VERSION ""

NS_ :

BS_:

BU_: BMS Host

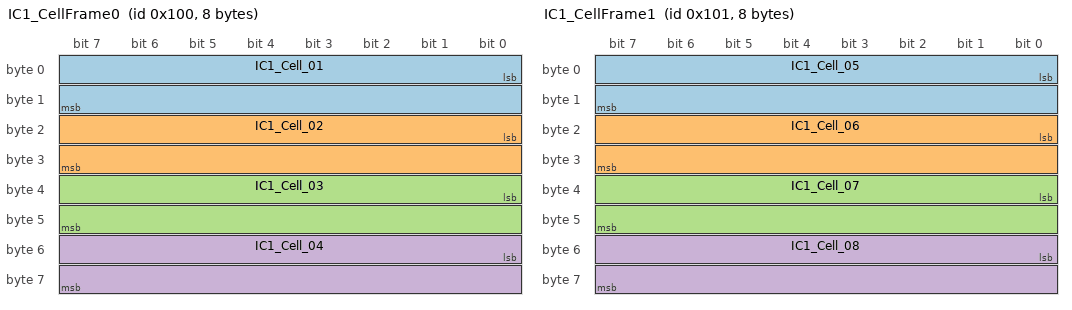
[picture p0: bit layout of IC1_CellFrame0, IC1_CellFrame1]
BO_ 256 IC1_CellFrame0: 8 BMS
 SG_ IC1_Cell_01 : 0|16@1+ (0.0001,0) [0|6.5535] "V" Host
 SG_ IC1_Cell_02 : 16|16@1+ (0.0001,0) [0|6.5535] "V" Host
 SG_ IC1_Cell_03 : 32|16@1+ (0.0001,0) [0|6.5535] "V" Host
 SG_ IC1_Cell_04 : 48|16@1+ (0.0001,0) [0|6.5535] "V" Host

BO_ 257 IC1_CellFrame1: 8 BMS
 SG_ IC1_Cell_05 : 0|16@1+ (0.0001,0) [0|6.5535] "V" Host
 SG_ IC1_Cell_06 : 16|16@1+ (0.0001,0) [0|6.5535] "V" Host
 SG_ IC1_Cell_07 : 32|16@1+ (0.0001,0) [0|6.5535] "V" Host
 SG_ IC1_Cell_08 : 48|16@1+ (0.0001,0) [0|6.5535] "V" Host

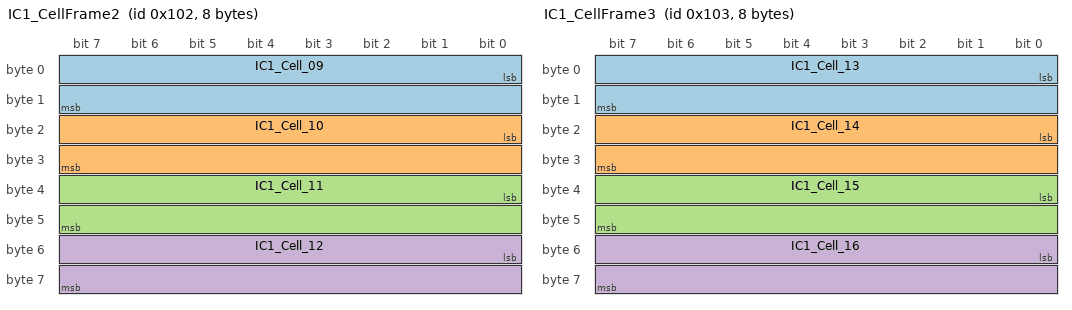
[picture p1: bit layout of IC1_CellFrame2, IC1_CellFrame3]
BO_ 258 IC1_CellFrame2: 8 BMS
 SG_ IC1_Cell_09 : 0|16@1+ (0.0001,0) [0|6.5535] "V" Host
 SG_ IC1_Cell_10 : 16|16@1+ (0.0001,0) [0|6.5535] "V" Host
 SG_ IC1_Cell_11 : 32|16@1+ (0.0001,0) [0|6.5535] "V" Host
 SG_ IC1_Cell_12 : 48|16@1+ (0.0001,0) [0|6.5535] "V" Host

BO_ 259 IC1_CellFrame3: 8 BMS
 SG_ IC1_Cell_13 : 0|16@1+ (0.0001,0) [0|6.5535] "V" Host
 SG_ IC1_Cell_14 : 16|16@1+ (0.0001,0) [0|6.5535] "V" Host
 SG_ IC1_Cell_15 : 32|16@1+ (0.0001,0) [0|6.5535] "V" Host
 SG_ IC1_Cell_16 : 48|16@1+ (0.0001,0) [0|6.5535] "V" Host

BO_ 260 IC1_CellFrame4: 8 BMS
 SG_ IC1_Cell_17 : 0|16@1+ (0.0001,0) [0|6.5535] "V" Host

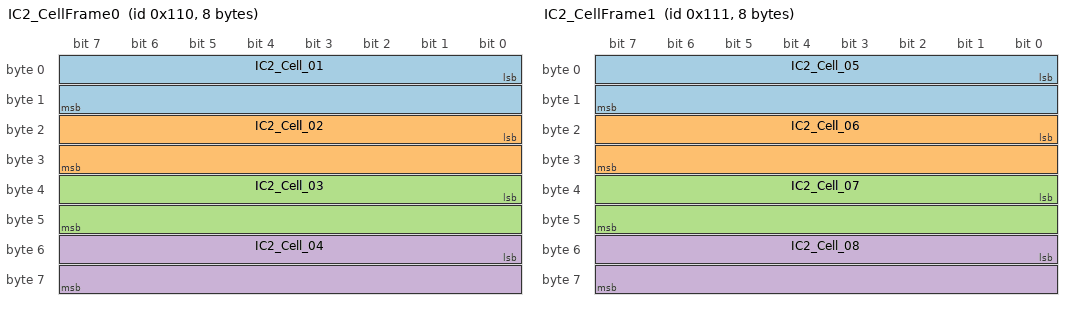
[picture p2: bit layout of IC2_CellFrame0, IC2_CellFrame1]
BO_ 272 IC2_CellFrame0: 8 BMS
 SG_ IC2_Cell_01 : 0|16@1+ (0.0001,0) [0|6.5535] "V" Host
 SG_ IC2_Cell_02 : 16|16@1+ (0.0001,0) [0|6.5535] "V" Host
 SG_ IC2_Cell_03 : 32|16@1+ (0.0001,0) [0|6.5535] "V" Host
 SG_ IC2_Cell_04 : 48|16@1+ (0.0001,0) [0|6.5535] "V" Host

BO_ 273 IC2_CellFrame1: 8 BMS
 SG_ IC2_Cell_05 : 0|16@1+ (0.0001,0) [0|6.5535] "V" Host
 SG_ IC2_Cell_06 : 16|16@1+ (0.0001,0) [0|6.5535] "V" Host
 SG_ IC2_Cell_07 : 32|16@1+ (0.0001,0) [0|6.5535] "V" Host
 SG_ IC2_Cell_08 : 48|16@1+ (0.0001,0) [0|6.5535] "V" Host

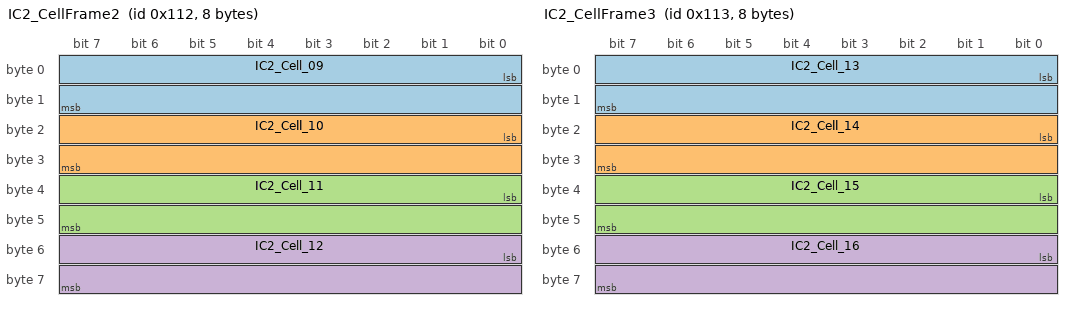
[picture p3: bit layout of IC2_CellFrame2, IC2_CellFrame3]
BO_ 274 IC2_CellFrame2: 8 BMS
 SG_ IC2_Cell_09 : 0|16@1+ (0.0001,0) [0|6.5535] "V" Host
 SG_ IC2_Cell_10 : 16|16@1+ (0.0001,0) [0|6.5535] "V" Host
 SG_ IC2_Cell_11 : 32|16@1+ (0.0001,0) [0|6.5535] "V" Host
 SG_ IC2_Cell_12 : 48|16@1+ (0.0001,0) [0|6.5535] "V" Host

BO_ 275 IC2_CellFrame3: 8 BMS
 SG_ IC2_Cell_13 : 0|16@1+ (0.0001,0) [0|6.5535] "V" Host
 SG_ IC2_Cell_14 : 16|16@1+ (0.0001,0) [0|6.5535] "V" Host
 SG_ IC2_Cell_15 : 32|16@1+ (0.0001,0) [0|6.5535] "V" Host
 SG_ IC2_Cell_16 : 48|16@1+ (0.0001,0) [0|6.5535] "V" Host

BO_ 276 IC2_CellFrame4: 8 BMS
 SG_ IC2_Cell_17 : 0|16@1+ (0.0001,0) [0|6.5535] "V" Host

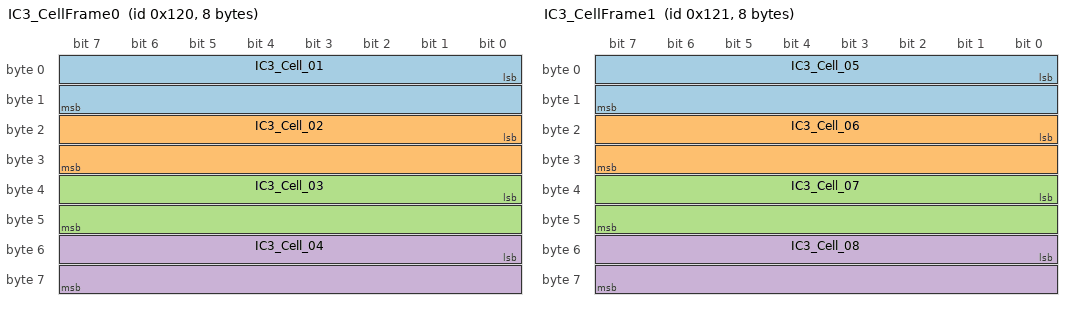
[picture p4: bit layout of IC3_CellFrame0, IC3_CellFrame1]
BO_ 288 IC3_CellFrame0: 8 BMS
 SG_ IC3_Cell_01 : 0|16@1+ (0.0001,0) [0|6.5535] "V" Host
 SG_ IC3_Cell_02 : 16|16@1+ (0.0001,0) [0|6.5535] "V" Host
 SG_ IC3_Cell_03 : 32|16@1+ (0.0001,0) [0|6.5535] "V" Host
 SG_ IC3_Cell_04 : 48|16@1+ (0.0001,0) [0|6.5535] "V" Host

BO_ 289 IC3_CellFrame1: 8 BMS
 SG_ IC3_Cell_05 : 0|16@1+ (0.0001,0) [0|6.5535] "V" Host
 SG_ IC3_Cell_06 : 16|16@1+ (0.0001,0) [0|6.5535] "V" Host
 SG_ IC3_Cell_07 : 32|16@1+ (0.0001,0) [0|6.5535] "V" Host
 SG_ IC3_Cell_08 : 48|16@1+ (0.0001,0) [0|6.5535] "V" Host

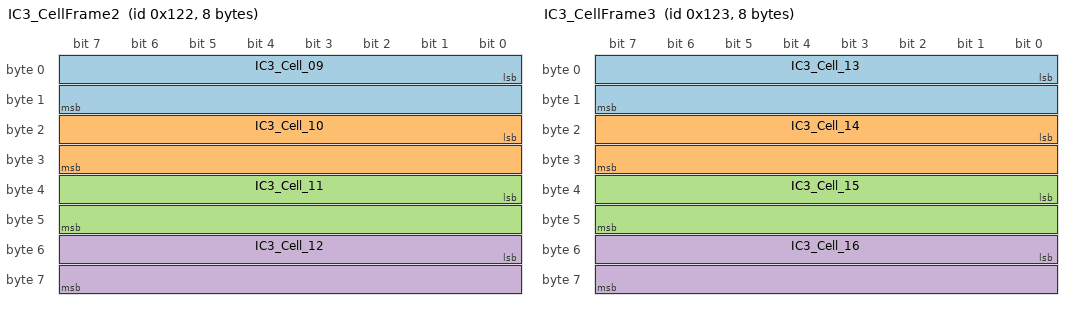
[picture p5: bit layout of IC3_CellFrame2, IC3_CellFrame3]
BO_ 290 IC3_CellFrame2: 8 BMS
 SG_ IC3_Cell_09 : 0|16@1+ (0.0001,0) [0|6.5535] "V" Host
 SG_ IC3_Cell_10 : 16|16@1+ (0.0001,0) [0|6.5535] "V" Host
 SG_ IC3_Cell_11 : 32|16@1+ (0.0001,0) [0|6.5535] "V" Host
 SG_ IC3_Cell_12 : 48|16@1+ (0.0001,0) [0|6.5535] "V" Host

BO_ 291 IC3_CellFrame3: 8 BMS
 SG_ IC3_Cell_13 : 0|16@1+ (0.0001,0) [0|6.5535] "V" Host
 SG_ IC3_Cell_14 : 16|16@1+ (0.0001,0) [0|6.5535] "V" Host
 SG_ IC3_Cell_15 : 32|16@1+ (0.0001,0) [0|6.5535] "V" Host
 SG_ IC3_Cell_16 : 48|16@1+ (0.0001,0) [0|6.5535] "V" Host

BO_ 292 IC3_CellFrame4: 8 BMS
 SG_ IC3_Cell_17 : 0|16@1+ (0.0001,0) [0|6.5535] "V" Host

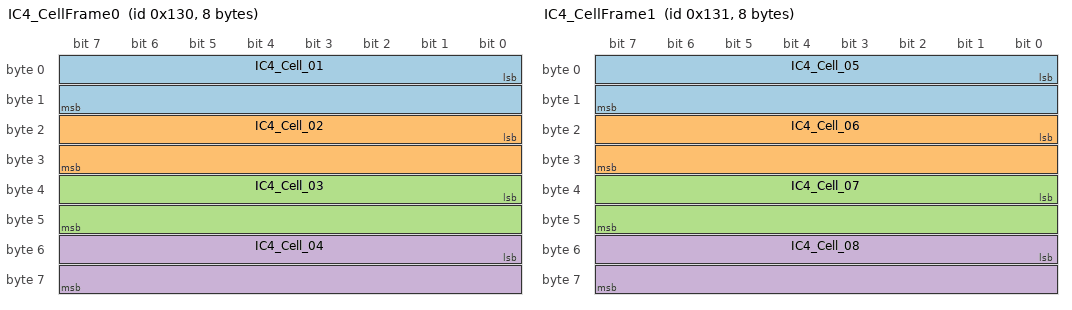
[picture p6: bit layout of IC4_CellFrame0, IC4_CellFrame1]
BO_ 304 IC4_CellFrame0: 8 BMS
 SG_ IC4_Cell_01 : 0|16@1+ (0.0001,0) [0|6.5535] "V" Host
 SG_ IC4_Cell_02 : 16|16@1+ (0.0001,0) [0|6.5535] "V" Host
 SG_ IC4_Cell_03 : 32|16@1+ (0.0001,0) [0|6.5535] "V" Host
 SG_ IC4_Cell_04 : 48|16@1+ (0.0001,0) [0|6.5535] "V" Host

BO_ 305 IC4_CellFrame1: 8 BMS
 SG_ IC4_Cell_05 : 0|16@1+ (0.0001,0) [0|6.5535] "V" Host
 SG_ IC4_Cell_06 : 16|16@1+ (0.0001,0) [0|6.5535] "V" Host
 SG_ IC4_Cell_07 : 32|16@1+ (0.0001,0) [0|6.5535] "V" Host
 SG_ IC4_Cell_08 : 48|16@1+ (0.0001,0) [0|6.5535] "V" Host

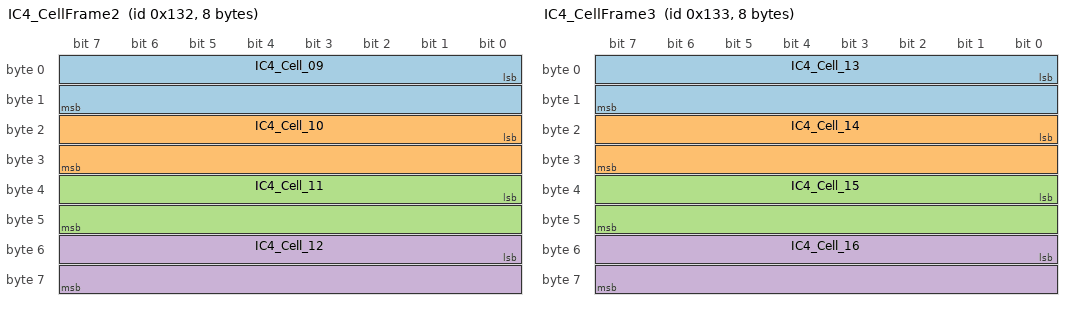
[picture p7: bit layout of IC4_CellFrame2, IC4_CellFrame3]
BO_ 306 IC4_CellFrame2: 8 BMS
 SG_ IC4_Cell_09 : 0|16@1+ (0.0001,0) [0|6.5535] "V" Host
 SG_ IC4_Cell_10 : 16|16@1+ (0.0001,0) [0|6.5535] "V" Host
 SG_ IC4_Cell_11 : 32|16@1+ (0.0001,0) [0|6.5535] "V" Host
 SG_ IC4_Cell_12 : 48|16@1+ (0.0001,0) [0|6.5535] "V" Host

BO_ 307 IC4_CellFrame3: 8 BMS
 SG_ IC4_Cell_13 : 0|16@1+ (0.0001,0) [0|6.5535] "V" Host
 SG_ IC4_Cell_14 : 16|16@1+ (0.0001,0) [0|6.5535] "V" Host
 SG_ IC4_Cell_15 : 32|16@1+ (0.0001,0) [0|6.5535] "V" Host
 SG_ IC4_Cell_16 : 48|16@1+ (0.0001,0) [0|6.5535] "V" Host

BO_ 308 IC4_CellFrame4: 8 BMS
 SG_ IC4_Cell_17 : 0|16@1+ (0.0001,0) [0|6.5535] "V" Host

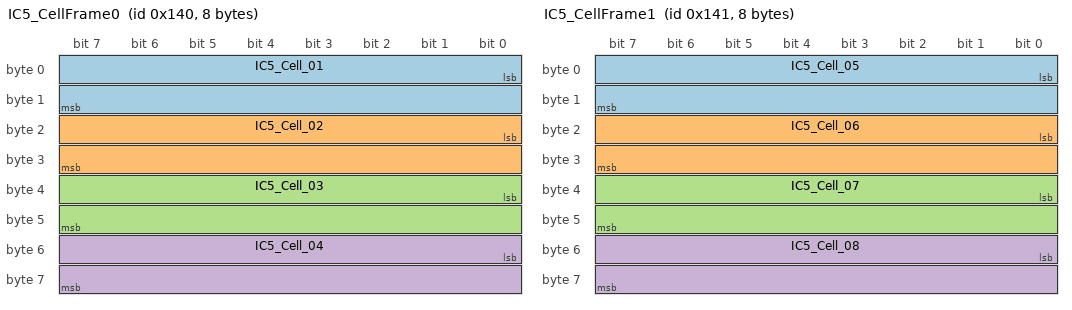
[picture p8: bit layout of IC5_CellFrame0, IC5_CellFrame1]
BO_ 320 IC5_CellFrame0: 8 BMS
 SG_ IC5_Cell_01 : 0|16@1+ (0.0001,0) [0|6.5535] "V" Host
 SG_ IC5_Cell_02 : 16|16@1+ (0.0001,0) [0|6.5535] "V" Host
 SG_ IC5_Cell_03 : 32|16@1+ (0.0001,0) [0|6.5535] "V" Host
 SG_ IC5_Cell_04 : 48|16@1+ (0.0001,0) [0|6.5535] "V" Host

BO_ 321 IC5_CellFrame1: 8 BMS
 SG_ IC5_Cell_05 : 0|16@1+ (0.0001,0) [0|6.5535] "V" Host
 SG_ IC5_Cell_06 : 16|16@1+ (0.0001,0) [0|6.5535] "V" Host
 SG_ IC5_Cell_07 : 32|16@1+ (0.0001,0) [0|6.5535] "V" Host
 SG_ IC5_Cell_08 : 48|16@1+ (0.0001,0) [0|6.5535] "V" Host

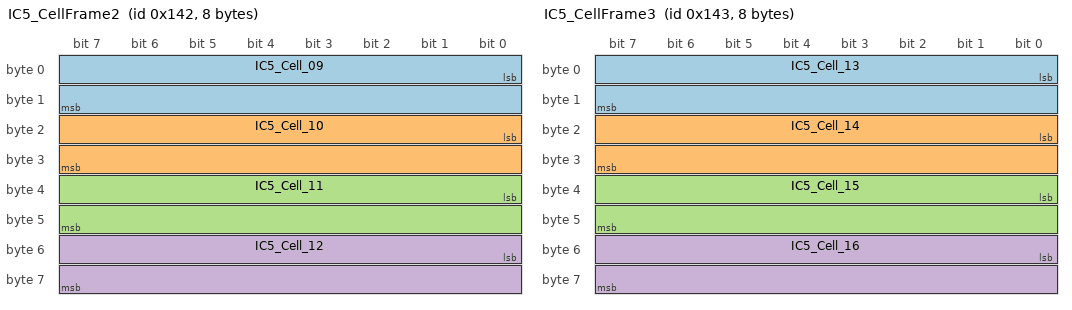
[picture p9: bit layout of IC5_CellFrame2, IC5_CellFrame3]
BO_ 322 IC5_CellFrame2: 8 BMS
 SG_ IC5_Cell_09 : 0|16@1+ (0.0001,0) [0|6.5535] "V" Host
 SG_ IC5_Cell_10 : 16|16@1+ (0.0001,0) [0|6.5535] "V" Host
 SG_ IC5_Cell_11 : 32|16@1+ (0.0001,0) [0|6.5535] "V" Host
 SG_ IC5_Cell_12 : 48|16@1+ (0.0001,0) [0|6.5535] "V" Host

BO_ 323 IC5_CellFrame3: 8 BMS
 SG_ IC5_Cell_13 : 0|16@1+ (0.0001,0) [0|6.5535] "V" Host
 SG_ IC5_Cell_14 : 16|16@1+ (0.0001,0) [0|6.5535] "V" Host
 SG_ IC5_Cell_15 : 32|16@1+ (0.0001,0) [0|6.5535] "V" Host
 SG_ IC5_Cell_16 : 48|16@1+ (0.0001,0) [0|6.5535] "V" Host

BO_ 324 IC5_CellFrame4: 8 BMS
 SG_ IC5_Cell_17 : 0|16@1+ (0.0001,0) [0|6.5535] "V" Host

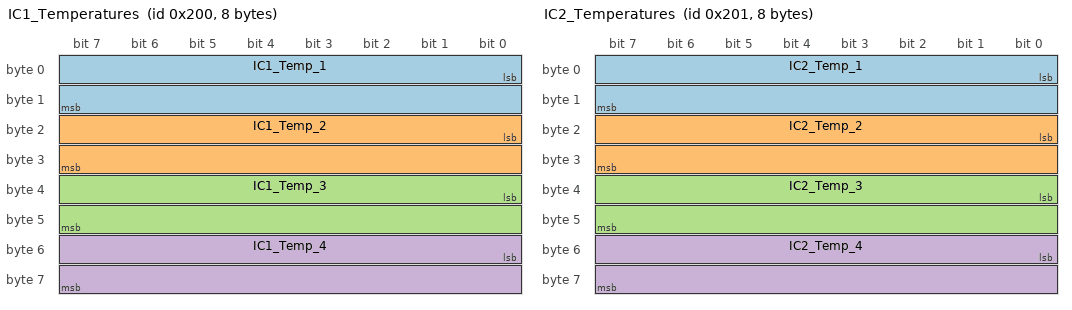
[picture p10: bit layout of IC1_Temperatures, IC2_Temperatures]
BO_ 512 IC1_Temperatures: 8 BMS
 SG_ IC1_Temp_1 : 0|16@1- (0.1,0) [-3276.8|3276.7] "degC" Host
 SG_ IC1_Temp_2 : 16|16@1- (0.1,0) [-3276.8|3276.7] "degC" Host
 SG_ IC1_Temp_3 : 32|16@1- (0.1,0) [-3276.8|3276.7] "degC" Host
 SG_ IC1_Temp_4 : 48|16@1- (0.1,0) [-3276.8|3276.7] "degC" Host

BO_ 513 IC2_Temperatures: 8 BMS
 SG_ IC2_Temp_1 : 0|16@1- (0.1,0) [-3276.8|3276.7] "degC" Host
 SG_ IC2_Temp_2 : 16|16@1- (0.1,0) [-3276.8|3276.7] "degC" Host
 SG_ IC2_Temp_3 : 32|16@1- (0.1,0) [-3276.8|3276.7] "degC" Host
 SG_ IC2_Temp_4 : 48|16@1- (0.1,0) [-3276.8|3276.7] "degC" Host

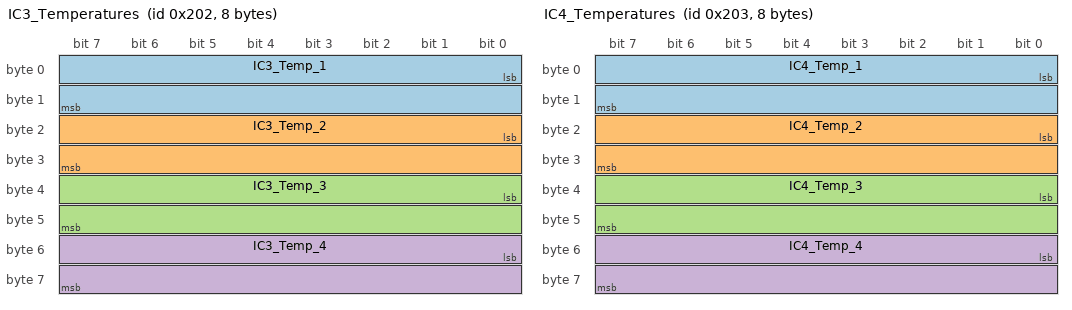
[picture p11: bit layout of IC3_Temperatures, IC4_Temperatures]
BO_ 514 IC3_Temperatures: 8 BMS
 SG_ IC3_Temp_1 : 0|16@1- (0.1,0) [-3276.8|3276.7] "degC" Host
 SG_ IC3_Temp_2 : 16|16@1- (0.1,0) [-3276.8|3276.7] "degC" Host
 SG_ IC3_Temp_3 : 32|16@1- (0.1,0) [-3276.8|3276.7] "degC" Host
 SG_ IC3_Temp_4 : 48|16@1- (0.1,0) [-3276.8|3276.7] "degC" Host

BO_ 515 IC4_Temperatures: 8 BMS
 SG_ IC4_Temp_1 : 0|16@1- (0.1,0) [-3276.8|3276.7] "degC" Host
 SG_ IC4_Temp_2 : 16|16@1- (0.1,0) [-3276.8|3276.7] "degC" Host
 SG_ IC4_Temp_3 : 32|16@1- (0.1,0) [-3276.8|3276.7] "degC" Host
 SG_ IC4_Temp_4 : 48|16@1- (0.1,0) [-3276.8|3276.7] "degC" Host

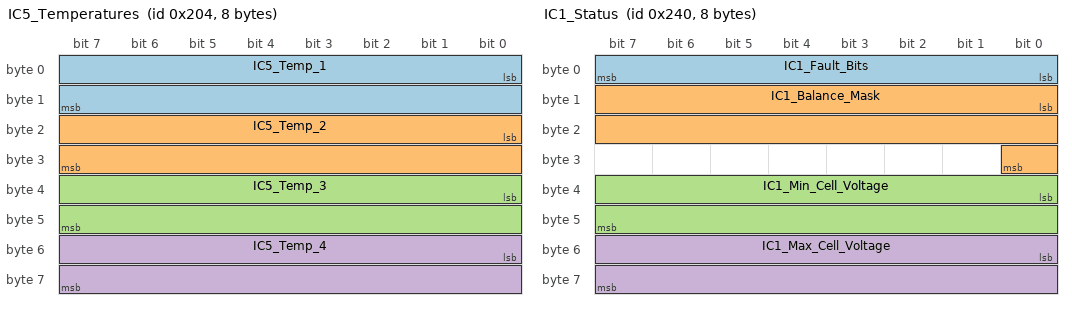
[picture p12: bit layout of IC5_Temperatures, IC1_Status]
BO_ 516 IC5_Temperatures: 8 BMS
 SG_ IC5_Temp_1 : 0|16@1- (0.1,0) [-3276.8|3276.7] "degC" Host
 SG_ IC5_Temp_2 : 16|16@1- (0.1,0) [-3276.8|3276.7] "degC" Host
 SG_ IC5_Temp_3 : 32|16@1- (0.1,0) [-3276.8|3276.7] "degC" Host
 SG_ IC5_Temp_4 : 48|16@1- (0.1,0) [-3276.8|3276.7] "degC" Host

BO_ 576 IC1_Status: 8 BMS
 SG_ IC1_Fault_Bits : 0|8@1+ (1,0) [0|255] "" Host
 SG_ IC1_Balance_Mask : 8|17@1+ (1,0) [0|131071] "" Host
 SG_ IC1_Min_Cell_Voltage : 32|16@1+ (0.0001,0) [0|6.5535] "V" Host
 SG_ IC1_Max_Cell_Voltage : 48|16@1+ (0.0001,0) [0|6.5535] "V" Host

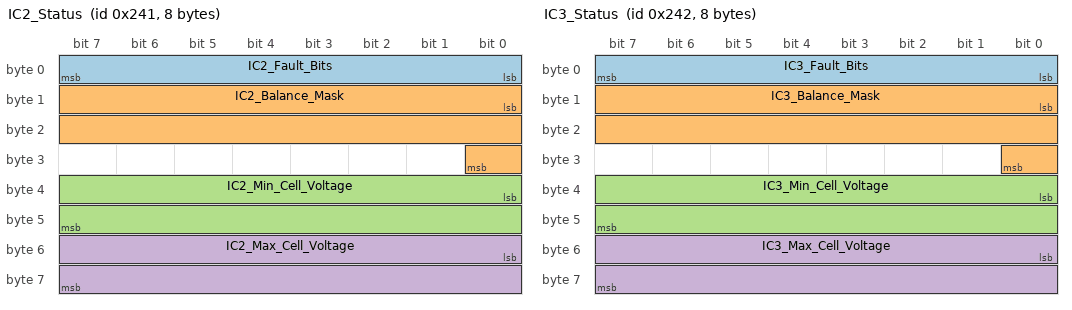
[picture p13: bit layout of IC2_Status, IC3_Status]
BO_ 577 IC2_Status: 8 BMS
 SG_ IC2_Fault_Bits : 0|8@1+ (1,0) [0|255] "" Host
 SG_ IC2_Balance_Mask : 8|17@1+ (1,0) [0|131071] "" Host
 SG_ IC2_Min_Cell_Voltage : 32|16@1+ (0.0001,0) [0|6.5535] "V" Host
 SG_ IC2_Max_Cell_Voltage : 48|16@1+ (0.0001,0) [0|6.5535] "V" Host

BO_ 578 IC3_Status: 8 BMS
 SG_ IC3_Fault_Bits : 0|8@1+ (1,0) [0|255] "" Host
 SG_ IC3_Balance_Mask : 8|17@1+ (1,0) [0|131071] "" Host
 SG_ IC3_Min_Cell_Voltage : 32|16@1+ (0.0001,0) [0|6.5535] "V" Host
 SG_ IC3_Max_Cell_Voltage : 48|16@1+ (0.0001,0) [0|6.5535] "V" Host

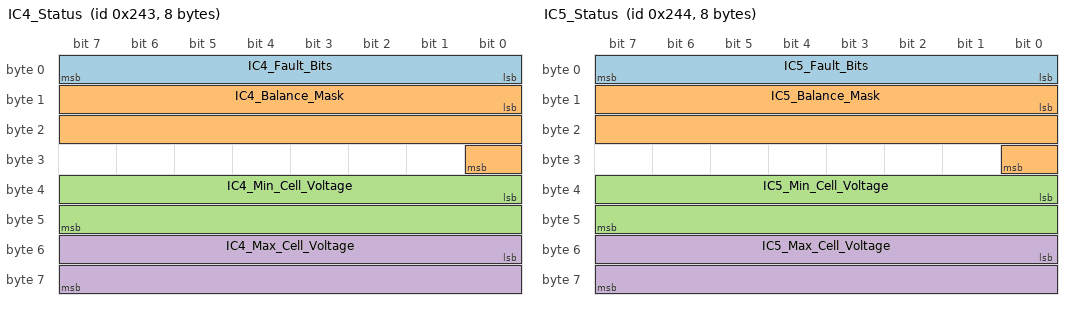
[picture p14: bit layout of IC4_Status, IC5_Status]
BO_ 579 IC4_Status: 8 BMS
 SG_ IC4_Fault_Bits : 0|8@1+ (1,0) [0|255] "" Host
 SG_ IC4_Balance_Mask : 8|17@1+ (1,0) [0|131071] "" Host
 SG_ IC4_Min_Cell_Voltage : 32|16@1+ (0.0001,0) [0|6.5535] "V" Host
 SG_ IC4_Max_Cell_Voltage : 48|16@1+ (0.0001,0) [0|6.5535] "V" Host

BO_ 580 IC5_Status: 8 BMS
 SG_ IC5_Fault_Bits : 0|8@1+ (1,0) [0|255] "" Host
 SG_ IC5_Balance_Mask : 8|17@1+ (1,0) [0|131071] "" Host
 SG_ IC5_Min_Cell_Voltage : 32|16@1+ (0.0001,0) [0|6.5535] "V" Host
 SG_ IC5_Max_Cell_Voltage : 48|16@1+ (0.0001,0) [0|6.5535] "V" Host

CM_ BO_ 256 "IC1 Cells 1-4, 100uV/bit";
CM_ BO_ 257 "IC1 Cells 5-8, 100uV/bit";
CM_ BO_ 258 "IC1 Cells 9-12, 100uV/bit";
CM_ BO_ 259 "IC1 Cells 13-16, 100uV/bit";
CM_ BO_ 260 "IC1 Cell 17, 100uV/bit";

CM_ BO_ 512 "IC1 Temperatures (NTC 1-4), 0.1 degC/bit";
CM_ BO_ 576 "IC1 BMS Status (Faults, Balance, Min/Max Voltage)";

CM_ SG_ 576 IC1_Fault_Bits "Bit 0: !BMS_OK, Bit 1: Temp Range ERR, Bit 2: Over Temp, Bit 3: Cell range ERR, Bit 4: Open Wire";
CM_ SG_ 576 IC1_Balance_Mask "17-bit mask for cells being discharged";

BA_DEF_  "BusType" STRING ;
BA_DEF_DEF_  "BusType" "CAN";
